# ESP32-S31 register map
Vendor: ESPRESSIF SYSTEMS (SHANGHAI) CO., LTD.; Series: ESP32 S-Series; File version: 1
CPU: RV32IMAFC r0p0, little endian, no MPU, FPU, 0 interrupt priority bits
Address unit: 32 bits
Registers are 32-bit, read-write, reset 0x0 unless marked. A register's access mark holds for its fields unless they carry their own. Offsets are from the block's base; [hi:lo] are bit positions; {n}, {i} and the like mark numbered series.

## EFUSE — eFuse Controller
Base 0x20715000
{0x0+4i} PGM_DATA{i} (i=0..7) — Represents pgm_data{i}
  [31:0] PGM_DATA — Configures the %sth 32-bit data to be programmed.
{0x20+4i} PGM_CHECK_VALUE{i} (i=0..2) — Represents pgm_check_value{i}
  [31:0] PGM_RS_DATA — Configures the %sth RS code to be programmed.
0x2C RD_WR_DIS ro — Represents rd_wr_dis
  [31:0] WR_DIS — Represents whether programming of individual eFuse memory bit is disabled. For mapping between the bits of this field and the eFuse memory bits, please refer to Table ef{tab:efuse-block0-para} and Table ef{tab:efuse-block-1-10-para}.\\1: Disabled\\0: Enabled\\
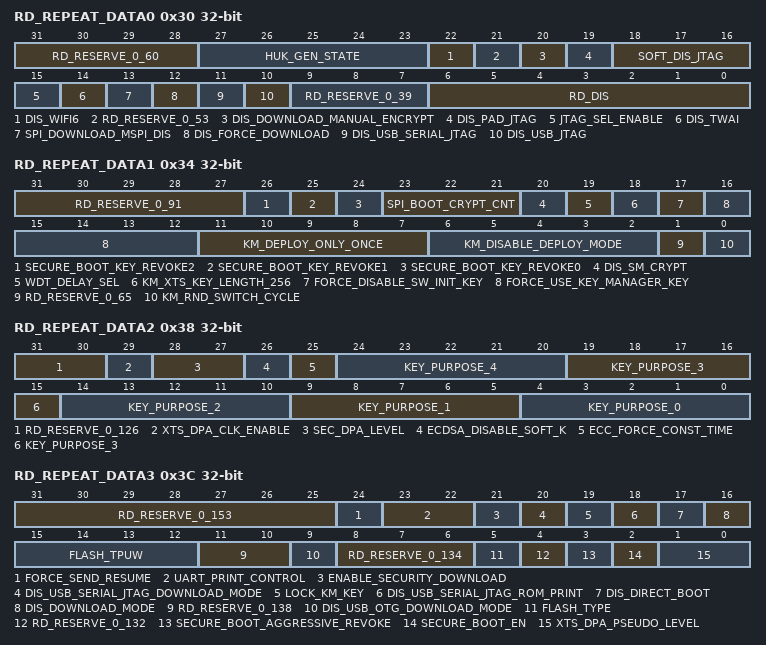
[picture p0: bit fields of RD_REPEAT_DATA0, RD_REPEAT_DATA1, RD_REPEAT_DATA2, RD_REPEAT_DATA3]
0x30 RD_REPEAT_DATA0 access per field — Represents rd_repeat_data
  [31:28] RD_RESERVE_0_60 rw
  [27:23] HUK_GEN_STATE ro — Represents the control of validation of HUK generate mode. Odd of 1 is invalid, even of 1 is valid.
  [22] DIS_WIFI6 ro — Represents thether the WIFI6 feature is enable or disabled. 1: WIFI6 is disable, 0: WIFI6 is enabled.
  [21] RD_RESERVE_0_53 rw
  [20] DIS_DOWNLOAD_MANUAL_ENCRYPT ro — Represents whether flash encrypt function is disabled or enabled(except in SPI boot mode).\\ 1: disabled\\ 0: enabled\\
  [19] DIS_PAD_JTAG ro — Represents whether JTAG is disabled in the hard way(permanently).\\ 1: disabled\\ 0: enabled\\
  [18:16] SOFT_DIS_JTAG ro — Represents whether JTAG is disabled in soft way.\\ Odd number: disabled\\ Even number: enabled\\
  [15] JTAG_SEL_ENABLE ro — Represents whether the selection between usb_to_jtag and pad_to_jtag through strapping gpio15 when both EFUSE_DIS_PAD_JTAG and EFUSE_DIS_USB_JTAG are equal to 0 is enabled or disabled.\\ 1: enabled\\ 0: disabled\\
  [14] DIS_TWAI ro — Represents whether TWAI function is disabled or enabled.\\ 1: disabled\\ 0: enabled\\
  [13] SPI_DOWNLOAD_MSPI_DIS ro — Represents whether SPI0 controller during boot_mode_download is disabled or enabled.\\ 1: disabled\\ 0: enabled\\
  [12] DIS_FORCE_DOWNLOAD ro — Represents whether the function that forces chip into download mode is disabled or enabled.\\ 1: disabled\\ 0: enabled\\
  [11] DIS_USB_SERIAL_JTAG ro — Represents whether USB-Serial-JTAG is disabled or enabled.\\ 1: disabled\\ 0: enabled\\
  [10] DIS_USB_JTAG ro — Represents whether the function of usb switch to jtag is disabled or enabled.\\ 1: disabled\\ 0: enabled\\
  [9:7] RD_RESERVE_0_39 rw
  [6:0] RD_DIS ro — Represents whether reading of individual eFuse block(block4~block9) is disabled or enabled.\\ 1: disabled\\ 0: enabled\\
0x34 RD_REPEAT_DATA1 access per field — Represents rd_repeat_data
  [31:27] RD_RESERVE_0_91 rw
  [26] SECURE_BOOT_KEY_REVOKE2 ro — Represents whether revoking third secure boot key is enabled or disabled.\\ 1: enabled\\ 0: disabled\\
  [25] SECURE_BOOT_KEY_REVOKE1 ro — Represents whether revoking second secure boot key is enabled or disabled.\\ 1: enabled\\ 0: disabled\\
  [24] SECURE_BOOT_KEY_REVOKE0 ro — Represents whether revoking first secure boot key is enabled or disabled.\\ 1: enabled\\ 0: disabled\\
  [23:21] SPI_BOOT_CRYPT_CNT ro — Represents whether SPI boot encrypt/decrypt is disabled or enabled.\\ Odd number of 1: enabled\\ Even number of 1: disabled\\
  [20] DIS_SM_CRYPT ro — Represents whether to disable all the SM crypto functions, including SM2, SM3.\\ 1: disabled\\ 0: enabled\\
  [19] WDT_DELAY_SEL ro — Represents the threshold level of the RTC watchdog STG0 timeout.\\0: Original threshold configuration value of STG0 *2 \\1: Original threshold configuration value of STG0 *4 \\2: Original threshold configuration value of STG0 *8 \\3: Original threshold configuration value of STG0 *16 \\
  [18] KM_XTS_KEY_LENGTH_256 ro — Represents whether to configure flash encryption use xts-128 key. else use xts-256 key. \\ 0: 128-bit key \\ 1: 256-bit key\\
  [17] FORCE_DISABLE_SW_INIT_KEY ro — Represents whether to disable software written init key, and force use efuse_init_key.
  [16:12] FORCE_USE_KEY_MANAGER_KEY ro — Represents whether corresponding key must come from key manager. 1 is true, 0 is false.\\ 0: ecsda\\ 1: flash\\ 2: reserved\\ 3: reserved\\ 4: psram\\
  [11:7] KM_DEPLOY_ONLY_ONCE ro — Represents whether corresponding key can only be deployed once. 1 is true, 0 is false. \\ 0: ecsda\\ 1: flash & spi boot srambler\\ 2: hmac & aes\\ 3: ds & rma nonce\\ 4: psram\\
  [6:2] KM_DISABLE_DEPLOY_MODE ro — Represents whether the deploy mode of key manager is disable or not. \\ 1: disabled \\ 0: enabled.\\ bit 0: ecsda, bit 1: flash & spi boot srambler, bit2: hmac & aes, bit3: ds & rma nonce, bit4: psram
  [1] RD_RESERVE_0_65 rw
  [0] KM_RND_SWITCH_CYCLE ro — Represents the control of key manager random number switch cycle. 0: control by register. 1: 8 km clk cycles. 2: 16 km cycles. 3: 32 km cycles
0x38 RD_REPEAT_DATA2 access per field — Represents rd_repeat_data
  [31:30] RD_RESERVE_0_126 rw
  [29] XTS_DPA_CLK_ENABLE ro — Represents whether to enable xts clock anti-dpa attack function.\\0: Disabled. \\1: Enabled\\
  [28:27] SEC_DPA_LEVEL ro — Represents the spa secure level by configuring the clock random divide mode.
  [26] ECDSA_DISABLE_SOFT_K ro — Represents whether permanently turn off ECDSA software set KEY.\\ 1: turn off\\ 0: turn on\\
  [25] ECC_FORCE_CONST_TIME ro — Represents whether permanently turn on ECC const-time mode. \\ 1: turn on\\ 0: turn off\\
  [5n+4:5n] KEY_PURPOSE_{n} ro (n=0..4) — Represents the purpose of Key{n}.
0x3C RD_REPEAT_DATA3 access per field — Represents rd_repeat_data
  [31:25] RD_RESERVE_0_153 rw
  [24] FORCE_SEND_RESUME ro — Represents whether ROM code is forced to send a resume command during SPI boot.\\ 1: forced\\ 0:not forced\\
  [23:22] UART_PRINT_CONTROL ro — Represents the type of UART printing.\\ 00: force enable printing\\ 01: enable printing when GPIO8 is reset at low level\\ 10: enable printing when GPIO8 is reset at high level\\ 11: force disable printing\\
  [21] ENABLE_SECURITY_DOWNLOAD ro — Represents whether security download is enabled or disabled.\\ 1: enabled\\ 0: disabled\\
  [20] DIS_USB_SERIAL_JTAG_DOWNLOAD_MODE ro — Represents whether the USB-Serial-JTAG download function is disabled or enabled.\\ 1: Disable\\ 0: Enable\\
  [19] LOCK_KM_KEY ro — Represetns whether to lock the efuse xts key.\\ 1. Lock\\ 0: Unlock\\
  [18] DIS_USB_SERIAL_JTAG_ROM_PRINT ro — Represents whether print from USB-Serial-JTAG is disabled or enabled.\\ 1: disabled\\ 0: enabled\\
  [17] DIS_DIRECT_BOOT ro — Represents whether direct boot mode is disabled or enabled.\\ 1: disabled\\ 0: enabled\\
  [16] DIS_DOWNLOAD_MODE ro — Represents whether Download mode is disabled or enabled.\\ 1: disabled\\ 0: enabled\\
  [15:12] FLASH_TPUW ro — Represents the flash waiting time after power-up, in unit of ms. When the value less than 15, the waiting time is the programmed value. Otherwise, the waiting time is 2 times the programmed value.
  [11:10] RD_RESERVE_0_138 rw
  [9] DIS_USB_OTG_DOWNLOAD_MODE ro — Set this bit to disable download via USB-OTG.
  [8:6] RD_RESERVE_0_134 rw
  [5] FLASH_TYPE ro — flash type: 0: nor flash, 1: nand flash
  [4] RD_RESERVE_0_132 rw
  [3] SECURE_BOOT_AGGRESSIVE_REVOKE ro — Represents whether revoking aggressive secure boot is enabled or disabled.\\ 1: enabled.\\ 0: disabled\\
  [2] SECURE_BOOT_EN ro — Represents whether secure boot is enabled or disabled.\\ 1: enabled\\ 0: disabled\\
  [1:0] XTS_DPA_PSEUDO_LEVEL ro — Represents the control of the xts pseudo-round anti-dpa attack function.\\ 0: controlled by register.\\ 1-3: the higer the value is, the more pseudo-rounds are inserted to the xts-aes calculation\\
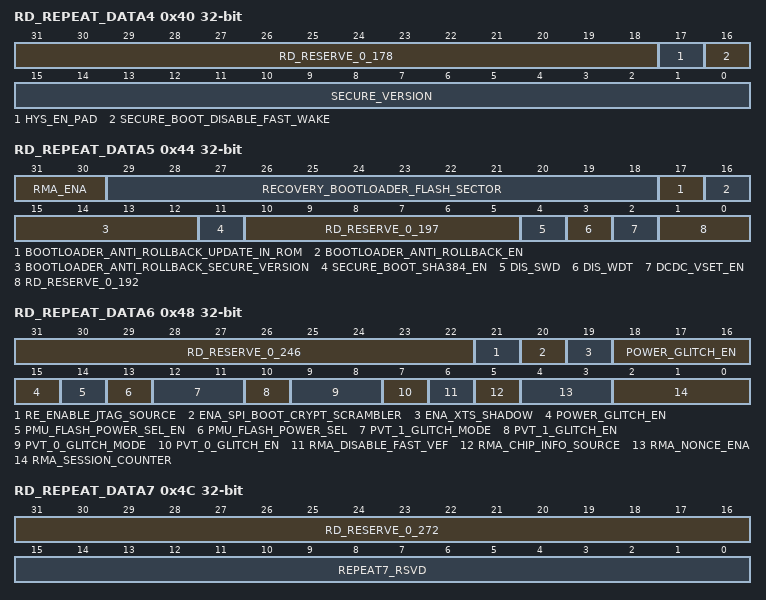
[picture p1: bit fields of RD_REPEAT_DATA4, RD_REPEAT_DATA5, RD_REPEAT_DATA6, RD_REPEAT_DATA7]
0x40 RD_REPEAT_DATA4 access per field — Represents rd_repeat_data
  [31:18] RD_RESERVE_0_178 rw
  [17] HYS_EN_PAD ro — Represents whether the hysteresis function of corresponding PAD is enabled.\\ 1: enabled\\ 0:disabled\\
  [16] SECURE_BOOT_DISABLE_FAST_WAKE ro — Represents whether FAST VERIFY ON WAKE is disabled or enabled when Secure Boot is enabled.\\ 1: disabled\\ 0: enabled\\
  [15:0] SECURE_VERSION ro — Represents the version used by ESP-IDF anti-rollback feature.
0x44 RD_REPEAT_DATA5 access per field — Represents rd_repeat_data
  [31:30] RMA_ENA ro — Represents whether rma function is supported in download mode.\\ 2'b01/2'b10: enabled\\2'b00/2'b11: disabled\\
  [29:18] RECOVERY_BOOTLOADER_FLASH_SECTOR ro — Represents the starting flash sector (flash sector size is 0x1000) of the recovery bootloader used by the ROM bootloader If the primary bootloader fails. 0 and 0xFFF - this feature is disabled.
  [17] BOOTLOADER_ANTI_ROLLBACK_UPDATE_IN_ROM ro — Represents whether the ani-rollback SECURE_VERSION will be updated from the ROM bootloader.\\1: Enable\\0: Disable\\
  [16] BOOTLOADER_ANTI_ROLLBACK_EN ro — Represents whether the ani-rollback check for the 2nd stage bootloader is enabled.\\1: Enabled\\0: Disabled\\
  [15:12] BOOTLOADER_ANTI_ROLLBACK_SECURE_VERSION ro — Represents the anti-rollback secure version of the 2nd stage bootloader used by the ROM bootloader.
  [11] SECURE_BOOT_SHA384_EN ro — Represents whether secure boot using SHA-384 is enabled. 0: Disable 1: Enable
  [10:5] RD_RESERVE_0_197 rw
  [4] DIS_SWD ro — Set this bit to disable super-watchdog.
  [3] DIS_WDT ro — Set this bit to disable watch dog.
  [2] DCDC_VSET_EN ro — Select dcdc vset use efuse_dcdc_vset.
  [1:0] RD_RESERVE_0_192 rw
0x48 RD_REPEAT_DATA6 access per field — Represents rd_repeat_data
  [31:22] RD_RESERVE_0_246 rw
  [21] RE_ENABLE_JTAG_SOURCE ro — Represents which Crypto peripheral is selected for renabling JTAG. \\ 0: RMA\\ 1: HMAC\\
  [20] ENA_SPI_BOOT_CRYPT_SCRAMBLER ro — Represents whether to enable ciphertext scrambler for external memory . \\ 0: Disabled\\ 1: Enabled\\
  [19] ENA_XTS_SHADOW ro — Represents whether to enable XTS-AES shadow core countermeasure against fault injection attacks. \\ 0: Disabled\\ 1: Enabled\\
  [18:15] POWER_GLITCH_EN ro — set these bit enable power glitch enable
  [14] PMU_FLASH_POWER_SEL_EN ro — FLASH power select enable signal. 1'b1 : validates EFUSE_PMU_FLASH_POWER_SEL 1'b0: invalidates EFUSE_PMU_FLASH_POWER_SEL
  [13] PMU_FLASH_POWER_SEL ro — FLASH power select.\\ 1'b1: use 3.3V\\1'b0: use 1.8V
  [12:11] PVT_1_GLITCH_MODE ro — Use to configure glitch mode
  [10] PVT_1_GLITCH_EN ro — Represents whether to enable PVT power glitch monitor function.\\1:Enable. \\0:Disable
  [9:8] PVT_0_GLITCH_MODE ro — Use to configure glitch mode
  [7] PVT_0_GLITCH_EN ro — Represents whether to enable PVT power glitch monitor function.\\1:Enable. \\0:Disable
  [6] RMA_DISABLE_FAST_VEF ro — Represents whether disable FAST_VEF in RMA session.\\1: disable\\0: enable\\
  [5] RMA_CHIP_INFO_SOURCE ro — Represents whether HUK_info is selected as the source for calculating CHIP_info in RMA.\\1: use HUK_info\\ 0: use UNIQ_id\\
  [4:3] RMA_NONCE_ENA ro — Represents whether random number NONCE is used in RMA and whether the KM module is used to generate the NONCE\\. 2'bx0: No NONCE\\ 2'b1x: Use KM generate NONCE.\\
  [2:0] RMA_SESSION_COUNTER ro — Represents the number of times the RMA session has been entered.
0x4C RD_REPEAT_DATA7 access per field — Represents rd_repeat_data
  [31:16] RD_RESERVE_0_272 rw
  [15:0] REPEAT7_RSVD ro — Reserved.
0x50 RD_MAC_SYS0 ro — Represents rd_mac_sys
  [31:0] MAC_0 — Represents MAC address. Low 32-bit.
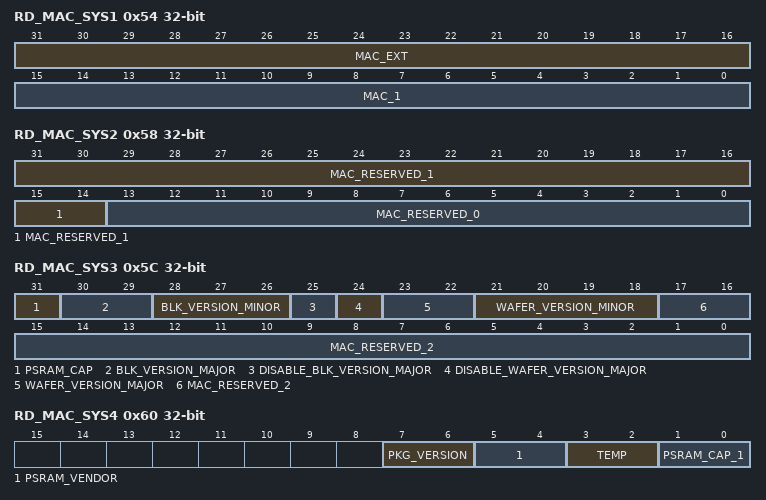
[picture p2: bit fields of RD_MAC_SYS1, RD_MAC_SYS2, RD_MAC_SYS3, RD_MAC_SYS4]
0x54 RD_MAC_SYS1 ro — Represents rd_mac_sys
  [31:16] MAC_EXT — Represents the extended bits of MAC address.
  [15:0] MAC_1 — Represents MAC address. High 16-bit.
0x58 RD_MAC_SYS2 ro — Represents rd_mac_sys
  [31:14] MAC_RESERVED_1 — Reserved.
  [13:0] MAC_RESERVED_0 — Reserved.
0x5C RD_MAC_SYS3 access per field — Represents rd_mac_sys
  [31] PSRAM_CAP rw
  [30:29] BLK_VERSION_MAJOR rw
  [28:26] BLK_VERSION_MINOR rw
  [25] DISABLE_BLK_VERSION_MAJOR rw
  [24] DISABLE_WAFER_VERSION_MAJOR rw
  [23:22] WAFER_VERSION_MAJOR rw
  [21:18] WAFER_VERSION_MINOR ro — Represents the first 14-bit of zeroth part of system data.
  [17:0] MAC_RESERVED_2 ro — Reserved.
0x60 RD_MAC_SYS4 access per field — Represents rd_mac_sys
  [7:6] PKG_VERSION rw
  [5:4] PSRAM_VENDOR rw
  [3:2] TEMP rw
  [1:0] PSRAM_CAP_1 ro — Represents the second 32-bit of zeroth part of system data.
0x64 RD_MAC_SYS5 ro — Represents rd_mac_sys
  [31:0] SYS_DATA_PART0_2 — Represents the third 32-bit of zeroth part of system data.
{0x68+4i} RD_SYS_PART1_DATA{i} (i=0..7) ro — Represents rd_sys_part1_data{i}
  [31:0] SYS_DATA_PART1 — Represents the zeroth 32-bit of first part of system data.
{0x88+4i} RD_USR_DATA{i} (i=0..7) ro — Represents rd_usr_data{i}
  [31:0] USR_DATA — Represents the zeroth 32-bit of block3 (user).
{0xA8+4i} RD_KEY0_DATA{i} (i=0..7) ro — Represents rd_key0_data{i}
  [31:0] KEY0_DATA — Represents the zeroth 32-bit of key0.
{0xC8+4i} RD_KEY1_DATA{i} (i=0..7) ro — Represents rd_key1_data{i}
  [31:0] KEY1_DATA — Represents the zeroth 32-bit of key1.
{0xE8+4i} RD_KEY2_DATA{i} (i=0..7) ro — Represents rd_key2_data{i}
  [31:0] KEY2_DATA — Represents the zeroth 32-bit of key2.
{0x108+4i} RD_KEY3_DATA{i} (i=0..7) ro — Represents rd_key3_data{i}
  [31:0] KEY3_DATA — Represents the zeroth 32-bit of key3.
{0x128+4i} RD_KEY4_DATA{i} (i=0..7) ro — Represents rd_key4_data{i}
  [31:0] KEY4_DATA — Represents the zeroth 32-bit of key4.
0x148 RD_SYS_PART2_DATA0 ro — Represents rd_sys_part2_data
  [31:0] SYS_DATA_PART2_0 — Represents the zeroth 32-bit of second part of system data.
0x14C RD_SYS_PART2_DATA1 ro — Represents rd_sys_part2_data
  [31:0] SYS_DATA_PART2_1 — Represents the first 32-bit of second part of system data.
0x150 RD_SYS_PART2_DATA2 ro — Represents rd_sys_part2_data
  [31:0] SYS_DATA_PART2_2 — Represents the second 32-bit of second part of system data.
0x154 RD_SYS_PART2_DATA3 ro — Represents rd_sys_part2_data
  [31:0] SYS_DATA_PART2_3 — Represents the third 32-bit of second part of system data.
0x158 RD_SYS_PART2_DATA4 ro — Represents rd_sys_part2_data
  [31:0] SYS_DATA_PART2_4 — Represents the fourth 32-bit of second part of system data.
0x15C RD_SYS_PART2_DATA5 ro — Represents rd_sys_part2_data
  [31:0] SYS_DATA_PART2_5 — Represents the fifth 32-bit of second part of system data.
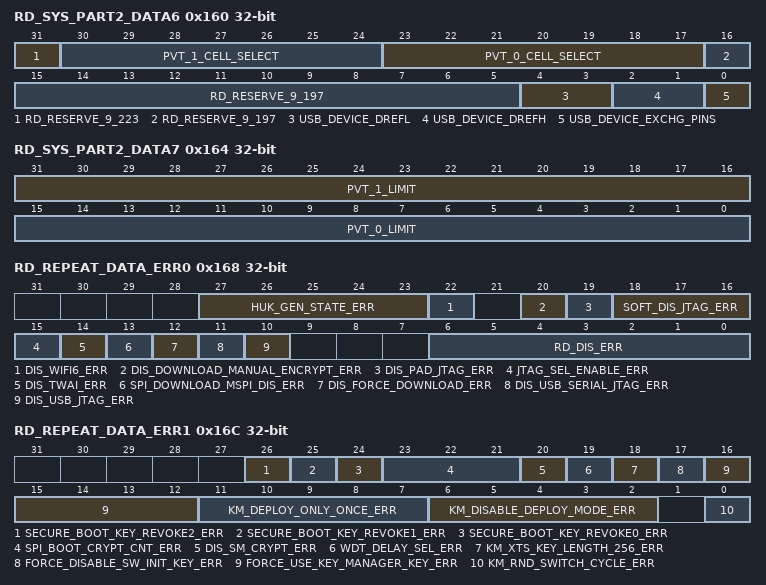
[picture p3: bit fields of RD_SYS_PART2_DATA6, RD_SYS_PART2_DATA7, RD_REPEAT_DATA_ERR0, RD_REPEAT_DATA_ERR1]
0x160 RD_SYS_PART2_DATA6 access per field — Represents rd_sys_part2_data
  [31] RD_RESERVE_9_223 rw
  [30:24] PVT_1_CELL_SELECT ro — Power glitch monitor PVT cell select.
  [23:17] PVT_0_CELL_SELECT ro — Power glitch monitor PVT cell select.
  [16:5] RD_RESERVE_9_197 rw
  [4:3] USB_DEVICE_DREFL ro — Represents the usb device single-end input low threhold, 0.8 V to 1.04 V with step of 80 mV.
  [2:1] USB_DEVICE_DREFH ro — Represents the single-end input threhold vrefh, 1.76 V to 2 V with step of 80 mV.
  [0] USB_DEVICE_EXCHG_PINS ro — Represents whether enable usb device exchange pins of D+ and D- or not. \\ 1: enabled\\ 0: disabled\\
0x164 RD_SYS_PART2_DATA7 ro — Represents rd_sys_part2_data
  [31:16] PVT_1_LIMIT — Power glitch monitor threthold.
  [15:0] PVT_0_LIMIT — Power glitch monitor threthold.
0x168 RD_REPEAT_DATA_ERR0 ro — Represents rd_repeat_data_err
  [27:23] HUK_GEN_STATE_ERR — Represents the programming error of EFUSE_HUK_GEN_STATE
  [22] DIS_WIFI6_ERR — Represents the programming error of EFUSE_DIS_WIFI6
  [20] DIS_DOWNLOAD_MANUAL_ENCRYPT_ERR — Represents the programming error of EFUSE_DIS_DOWNLOAD_MANUAL_ENCRYPT
  [19] DIS_PAD_JTAG_ERR — Represents the programming error of EFUSE_DIS_PAD_JTAG
  [18:16] SOFT_DIS_JTAG_ERR — Represents the programming error of EFUSE_SOFT_DIS_JTAG
  [15] JTAG_SEL_ENABLE_ERR — Represents the programming error of EFUSE_JTAG_SEL_ENABLE
  [14] DIS_TWAI_ERR — Represents the programming error of EFUSE_DIS_TWAI
  [13] SPI_DOWNLOAD_MSPI_DIS_ERR — Represents the programming error of EFUSE_SPI_DOWNLOAD_MSPI_DIS
  [12] DIS_FORCE_DOWNLOAD_ERR — Represents the programming error of EFUSE_DIS_FORCE_DOWNLOAD
  [11] DIS_USB_SERIAL_JTAG_ERR — Represents the programming error of EFUSE_DIS_USB_SERIAL_JTAG
  [10] DIS_USB_JTAG_ERR — Represents the programming error of EFUSE_DIS_USB_JTAG
  [6:0] RD_DIS_ERR — Represents the programming error of EFUSE_RD_DIS
0x16C RD_REPEAT_DATA_ERR1 ro — Represents rd_repeat_data_err
  [26] SECURE_BOOT_KEY_REVOKE2_ERR — Represents the programming error of EFUSE_SECURE_BOOT_KEY_REVOKE2
  [25] SECURE_BOOT_KEY_REVOKE1_ERR — Represents the programming error of EFUSE_SECURE_BOOT_KEY_REVOKE1
  [24] SECURE_BOOT_KEY_REVOKE0_ERR — Represents the programming error of EFUSE_SECURE_BOOT_KEY_REVOKE0
  [23:21] SPI_BOOT_CRYPT_CNT_ERR — Represents the programming error of EFUSE_SPI_BOOT_CRYPT_CNT
  [20] DIS_SM_CRYPT_ERR — Represents the programming error of EFUSE_DIS_SM_CRYPT
  [19] WDT_DELAY_SEL_ERR — Represents the programming error of EFUSE_WDT_DELAY_SEL
  [18] KM_XTS_KEY_LENGTH_256_ERR — Represents the programming error of EFUSE_KM_XTS_KEY_LENGTH_256
  [17] FORCE_DISABLE_SW_INIT_KEY_ERR — Represents the programming error of EFUSE_FORCE_DISABLE_SW_INIT_KEY
  [16:12] FORCE_USE_KEY_MANAGER_KEY_ERR — Represents the programming error of EFUSE_FORCE_USE_KEY_MANAGER_KEY
  [11:7] KM_DEPLOY_ONLY_ONCE_ERR — Represents the programming error of EFUSE_KM_DEPLOY_ONLY_ONCE
  [6:2] KM_DISABLE_DEPLOY_MODE_ERR — Represents the programming error of EFUSE_KM_DISABLE_DEPLOY_MODE
  [0] KM_RND_SWITCH_CYCLE_ERR — Represents the programming error of EFUSE_KM_RND_SWITCH_CYCLE
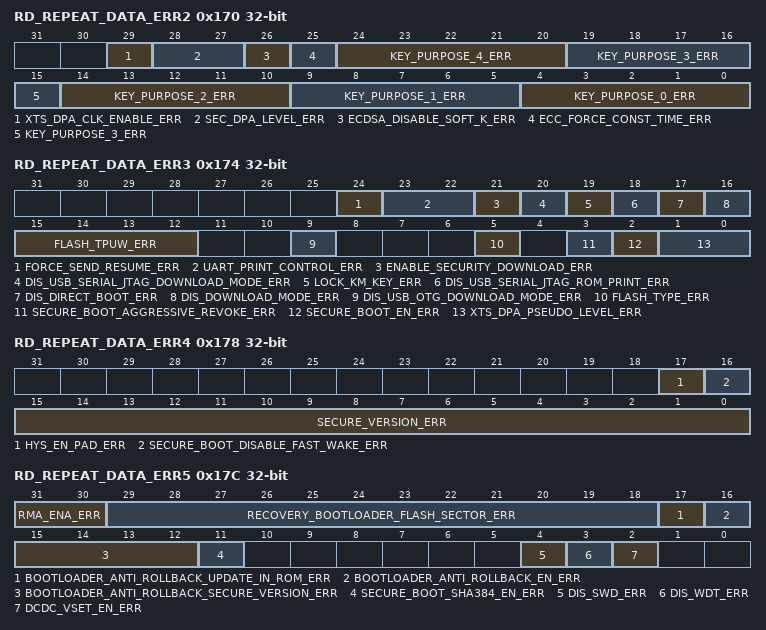
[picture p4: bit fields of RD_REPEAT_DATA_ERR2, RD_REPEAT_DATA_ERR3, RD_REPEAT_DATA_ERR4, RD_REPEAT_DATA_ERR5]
0x170 RD_REPEAT_DATA_ERR2 ro — Represents rd_repeat_data_err
  [29] XTS_DPA_CLK_ENABLE_ERR — Represents the programming error of EFUSE_XTS_DPA_CLK_ENABLE
  [28:27] SEC_DPA_LEVEL_ERR — Represents the programming error of EFUSE_SEC_DPA_LEVEL
  [26] ECDSA_DISABLE_SOFT_K_ERR — Represents the programming error of EFUSE_ECDSA_DISABLE_SOFT_K
  [25] ECC_FORCE_CONST_TIME_ERR — Represents the programming error of EFUSE_ECC_FORCE_CONST_TIME
  [5n+4:5n] KEY_PURPOSE_{n}_ERR (n=0..4) — Represents the programming error of EFUSE_KEY_PURPOSE_{n}
0x174 RD_REPEAT_DATA_ERR3 ro — Represents rd_repeat_data_err
  [24] FORCE_SEND_RESUME_ERR — Represents the programming error of EFUSE_FORCE_SEND_RESUME
  [23:22] UART_PRINT_CONTROL_ERR — Represents the programming error of EFUSE_UART_PRINT_CONTROL
  [21] ENABLE_SECURITY_DOWNLOAD_ERR — Represents the programming error of EFUSE_ENABLE_SECURITY_DOWNLOAD
  [20] DIS_USB_SERIAL_JTAG_DOWNLOAD_MODE_ERR — Represents the programming error of EFUSE_DIS_USB_SERIAL_JTAG_DOWNLOAD_MODE
  [19] LOCK_KM_KEY_ERR — Represents the programming error of EFUSE_LOCK_KM_KEY
  [18] DIS_USB_SERIAL_JTAG_ROM_PRINT_ERR — Represents the programming error of EFUSE_DIS_USB_SERIAL_JTAG_ROM_PRINT
  [17] DIS_DIRECT_BOOT_ERR — Represents the programming error of EFUSE_DIS_DIRECT_BOOT
  [16] DIS_DOWNLOAD_MODE_ERR — Represents the programming error of EFUSE_DIS_DOWNLOAD_MODE
  [15:12] FLASH_TPUW_ERR — Represents the programming error of EFUSE_FLASH_TPUW
  [9] DIS_USB_OTG_DOWNLOAD_MODE_ERR — Represents the programming error of EFUSE_DIS_USB_OTG_DOWNLOAD_MODE
  [5] FLASH_TYPE_ERR — Represents the programming error of EFUSE_FLASH_TYPE
  [3] SECURE_BOOT_AGGRESSIVE_REVOKE_ERR — Represents the programming error of EFUSE_SECURE_BOOT_AGGRESSIVE_REVOKE
  [2] SECURE_BOOT_EN_ERR — Represents the programming error of EFUSE_SECURE_BOOT_EN
  [1:0] XTS_DPA_PSEUDO_LEVEL_ERR — Represents the programming error of EFUSE_XTS_DPA_PSEUDO_LEVEL
0x178 RD_REPEAT_DATA_ERR4 ro — Represents rd_repeat_data_err
  [17] HYS_EN_PAD_ERR — Represents the programming error of EFUSE_HYS_EN_PAD
  [16] SECURE_BOOT_DISABLE_FAST_WAKE_ERR — Represents the programming error of EFUSE_SECURE_BOOT_DISABLE_FAST_WAKE
  [15:0] SECURE_VERSION_ERR — Represents the programming error of EFUSE_SECURE_VERSION
0x17C RD_REPEAT_DATA_ERR5 ro — Represents rd_repeat_data_err
  [31:30] RMA_ENA_ERR — Represents the programming error of EFUSE_RMA_ENA
  [29:18] RECOVERY_BOOTLOADER_FLASH_SECTOR_ERR — Represents the programming error of EFUSE_RECOVERY_BOOTLOADER_FLASH_SECTOR
  [17] BOOTLOADER_ANTI_ROLLBACK_UPDATE_IN_ROM_ERR — Represents the programming error of EFUSE_BOOTLOADER_ANTI_ROLLBACK_UPDATE_IN_ROM
  [16] BOOTLOADER_ANTI_ROLLBACK_EN_ERR — Represents the programming error of EFUSE_BOOTLOADER_ANTI_ROLLBACK_EN
  [15:12] BOOTLOADER_ANTI_ROLLBACK_SECURE_VERSION_ERR — Represents the programming error of EFUSE_BOOTLOADER_ANTI_ROLLBACK_SECURE_VERSION
  [11] SECURE_BOOT_SHA384_EN_ERR — Represents the programming error of EFUSE_SECURE_BOOT_SHA384_EN
  [4] DIS_SWD_ERR — Represents the programming error of EFUSE_DIS_SWD
  [3] DIS_WDT_ERR — Represents the programming error of EFUSE_DIS_WDT
  [2] DCDC_VSET_EN_ERR — Represents the programming error of EFUSE_DCDC_VSET_EN
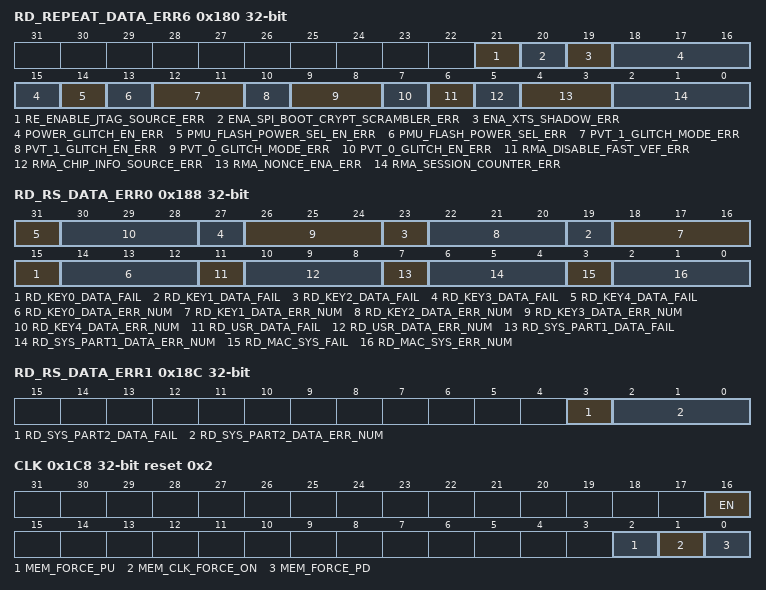
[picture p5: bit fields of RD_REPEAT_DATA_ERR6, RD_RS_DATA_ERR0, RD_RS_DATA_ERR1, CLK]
0x180 RD_REPEAT_DATA_ERR6 ro — Represents rd_repeat_data_err
  [21] RE_ENABLE_JTAG_SOURCE_ERR — Represents the programming error of EFUSE_RE_ENABLE_JTAG_SOURCE
  [20] ENA_SPI_BOOT_CRYPT_SCRAMBLER_ERR — Represents the programming error of EFUSE_ENA_SPI_BOOT_CRYPT_SCRAMBLER
  [19] ENA_XTS_SHADOW_ERR — Represents the programming error of EFUSE_ENA_XTS_SHADOW
  [18:15] POWER_GLITCH_EN_ERR — Represents the programming error of EFUSE_POWER_GLITCH_EN
  [14] PMU_FLASH_POWER_SEL_EN_ERR — Represents the programming error of EFUSE_PMU_FLASH_POWER_SEL_EN
  [13] PMU_FLASH_POWER_SEL_ERR — Represents the programming error of EFUSE_PMU_FLASH_POWER_SEL
  [12:11] PVT_1_GLITCH_MODE_ERR — Represents the programming error of EFUSE_PVT_1_GLITCH_MODE
  [10] PVT_1_GLITCH_EN_ERR — Represents the programming error of EFUSE_PVT_1_GLITCH_EN
  [9:8] PVT_0_GLITCH_MODE_ERR — Represents the programming error of EFUSE_PVT_0_GLITCH_MODE
  [7] PVT_0_GLITCH_EN_ERR — Represents the programming error of EFUSE_PVT_0_GLITCH_EN
  [6] RMA_DISABLE_FAST_VEF_ERR — Represents the programming error of EFUSE_RMA_DISABLE_FAST_VEF
  [5] RMA_CHIP_INFO_SOURCE_ERR — Represents the programming error of EFUSE_RMA_CHIP_INFO_SOURCE
  [4:3] RMA_NONCE_ENA_ERR — Represents the programming error of EFUSE_RMA_NONCE_ENA
  [2:0] RMA_SESSION_COUNTER_ERR — Represents the programming error of EFUSE_RMA_SESSION_COUNTER
0x184 RD_REPEAT_DATA_ERR7 ro — Represents rd_repeat_data_err
  [15:0] REPEAT7_RSVD_ERR — Represents the programming error of EFUSE_REPEAT7_RSVD
0x188 RD_RS_DATA_ERR0 ro — Represents rd_rs_data_err
  [4n+15] RD_KEY{n}_DATA_FAIL (n=0..4) — Represents error status of register.\\0: Means no failure and that the data of rd_key{n}_data is reliable\\ 1: Means that programming rd_key{n}_data failed and the number of error bytes is over 6.
  [4n+14:4n+12] RD_KEY{n}_DATA_ERR_NUM (n=0..4) — Represents the error number of registers.\\The value of this signal means the number of error bytes in rd_key{n}_data
  [11] RD_USR_DATA_FAIL — Represents error status of register.\\0: Means no failure and that the data of rd_usr_data is reliable\\ 1: Means that programming rd_usr_data failed and the number of error bytes is over 6.
  [10:8] RD_USR_DATA_ERR_NUM — Represents the error number of registers.\\The value of this signal means the number of error bytes in rd_usr_data
  [7] RD_SYS_PART1_DATA_FAIL — Represents error status of register.\\0: Means no failure and that the data of rd_sys_part1_data is reliable\\ 1: Means that programming rd_sys_part1_data failed and the number of error bytes is over 6.
  [6:4] RD_SYS_PART1_DATA_ERR_NUM — Represents the error number of registers.\\The value of this signal means the number of error bytes in rd_sys_part1_data
  [3] RD_MAC_SYS_FAIL — Represents error status of register.\\0: Means no failure and that the data of rd_mac_sys is reliable\\ 1: Means that programming rd_mac_sys failed and the number of error bytes is over 6.
  [2:0] RD_MAC_SYS_ERR_NUM — Represents the error number of registers.\\The value of this signal means the number of error bytes in rd_mac_sys
0x18C RD_RS_DATA_ERR1 ro — Represents rd_rs_data_err
  [3] RD_SYS_PART2_DATA_FAIL — Represents error status of register.\\0: Means no failure and that the data of rd_sys_part2_data is reliable\\ 1: Means that programming rd_sys_part2_data failed and the number of error bytes is over 6.
  [2:0] RD_SYS_PART2_DATA_ERR_NUM — Represents the error number of registers.\\The value of this signal means the number of error bytes in rd_sys_part2_data
0x190 DATE reset 0x2509194 — eFuse version register.
  [27:0] DATE — Represents eFuse version. Date:2025-09-19 19:52:16, ScriptRev:abfb97fc087287a4eacd02828cb3ca8dd0d0e75f
0x1C8 CLK reset 0x2 — eFuse clcok configuration register.
  [16] EN — Configures whether to force enable eFuse register configuration clock signal.\\ 1: Force\\ 0: The clock is enabled only during the reading and writing of registers\\
  [2] MEM_FORCE_PU — Configures whether to force power up eFuse SRAM.\\ 1: Force\\ 0: No effect\\
  [1] MEM_CLK_FORCE_ON — Configures whether to force activate clock signal of eFuse SRAM.\\ 1: Force activate\\ 0: No effect\\
  [0] MEM_FORCE_PD — Configures whether to force power down eFuse SRAM.\\ 1: Force\\ 0: No effect\\
0x1CC CONF — eFuse operation mode configuraiton register
  [15:0] OP_CODE — Configures operation command type.\\ 0x5A5A: Program operation command\\ 0x5AA5: Read operation command\\ Other values: No effect\\
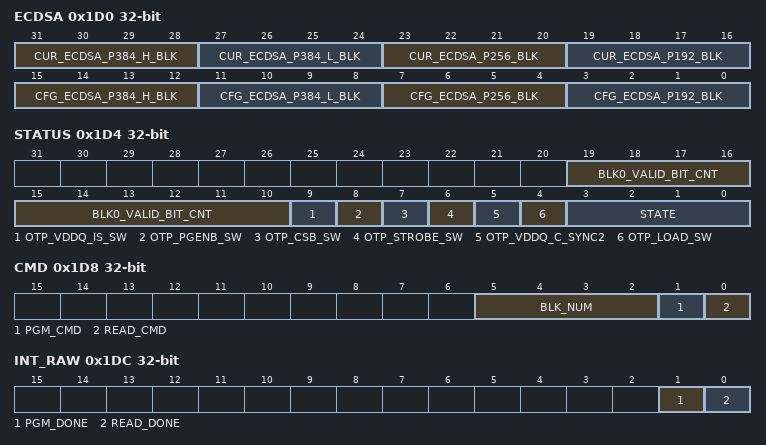
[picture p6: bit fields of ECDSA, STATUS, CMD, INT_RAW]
0x1D0 ECDSA access per field — eFuse status register.
  [31:28] CUR_ECDSA_P384_H_BLK ro — Represents which block is used for ECDSA P384 key high part output.
  [27:24] CUR_ECDSA_P384_L_BLK ro — Represents which block is used for ECDSA P384 key low part output.
  [23:20] CUR_ECDSA_P256_BLK ro — Represents which block is used for ECDSA P256 key output.
  [19:16] CUR_ECDSA_P192_BLK ro — Represents which block is used for ECDSA P192 key output.
  [15:12] CFG_ECDSA_P384_H_BLK rw — Configures which block to use for ECDSA P256 key high part output.
  [11:8] CFG_ECDSA_P384_L_BLK rw — Configures which block to use for ECDSA P384 key low part output.
  [7:4] CFG_ECDSA_P256_BLK rw — Configures which block to use for ECDSA P256 key output.
  [3:0] CFG_ECDSA_P192_BLK rw — Configures which block to use for ECDSA P192 key output.
0x1D4 STATUS ro — eFuse status register.
  [19:10] BLK0_VALID_BIT_CNT — Represents the number of block valid bit.
  [9] OTP_VDDQ_IS_SW — Represents the value of OTP_VDDQ_IS_SW.
  [8] OTP_PGENB_SW — Represents the value of OTP_PGENB_SW.
  [7] OTP_CSB_SW — Represents the value of OTP_CSB_SW.
  [6] OTP_STROBE_SW — Represents the value of OTP_STROBE_SW.
  [5] OTP_VDDQ_C_SYNC2 — Represents the value of OTP_VDDQ_C_SYNC2.
  [4] OTP_LOAD_SW — Represents the value of OTP_LOAD_SW.
  [3:0] STATE — Represents the state of the eFuse state machine.\\ 0: Reset state, the initial state after power-up\\ 1: Idle state\\ Other values: Non-idle state\\
0x1D8 CMD — eFuse command register.
  [5:2] BLK_NUM — Configures the serial number of the block to be programmed. Value 0-10 corresponds to block number 0-10, respectively.
  [1] PGM_CMD — Configures whether to send programing commands.\\ 1: Send\\ 0: No effect\\
  [0] READ_CMD — Configures whether to send read commands.\\ 1: Send\\ 0: No effect\\
0x1DC INT_RAW ro — eFuse raw interrupt register.
  [1] PGM_DONE — The raw interrupt status of EFUSE_PGM_DONE_INT.
  [0] READ_DONE — The raw interrupt status of EFUSE_READ_DONE_INT.
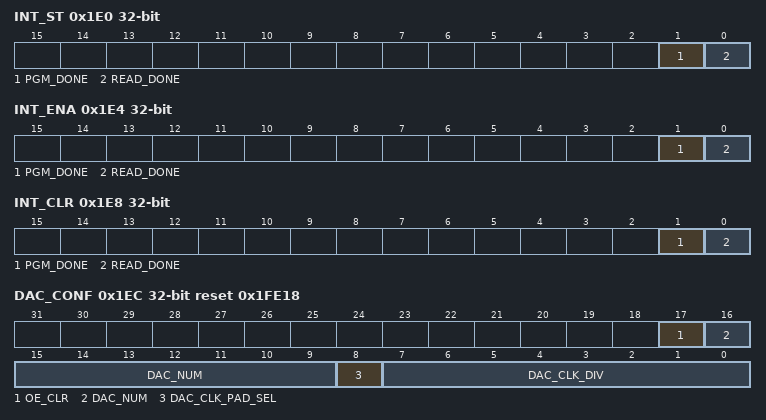
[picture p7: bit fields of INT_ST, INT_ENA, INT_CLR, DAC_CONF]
0x1E0 INT_ST ro — eFuse interrupt status register.
  [1] PGM_DONE — The masked interrupt status of EFUSE_PGM_DONE_INT.
  [0] READ_DONE — The masked interrupt status of EFUSE_READ_DONE_INT.
0x1E4 INT_ENA — eFuse interrupt enable register.
  [1] PGM_DONE — Write 1 to enable EFUSE_PGM_DONE_INT.
  [0] READ_DONE — Write 1 to enable EFUSE_READ_DONE_INT.
0x1E8 INT_CLR wo — eFuse interrupt clear register.
  [1] PGM_DONE write-1-clears — Write 1 to clear EFUSE_PGM_DONE_INT.
  [0] READ_DONE write-1-clears — Write 1 to clear EFUSE_READ_DONE_INT.
0x1EC DAC_CONF reset 0x1FE18 — Controls the eFuse programming voltage.
  [17] OE_CLR — Configures whether to reduce the power supply of programming voltage.\\ 0: Not reduce\\ 1: Reduce\\
  [16:9] DAC_NUM — Configures clock cycles for programming voltage to rise (VDDQ 2.5V, ramp-up 10mV for one-cycle). Measurement unit: a clock cycle divided by EFUSE_DAC_CLK_DIV.
  [8] DAC_CLK_PAD_SEL — Don't care.
  [7:0] DAC_CLK_DIV — Configures the division factor of the rising clock of the programming voltage (ramp-up slew rate be slower than 2.5V/250us, and ramp-up 10mV for one-cycle, so reg_dac_clk_div > fclk).
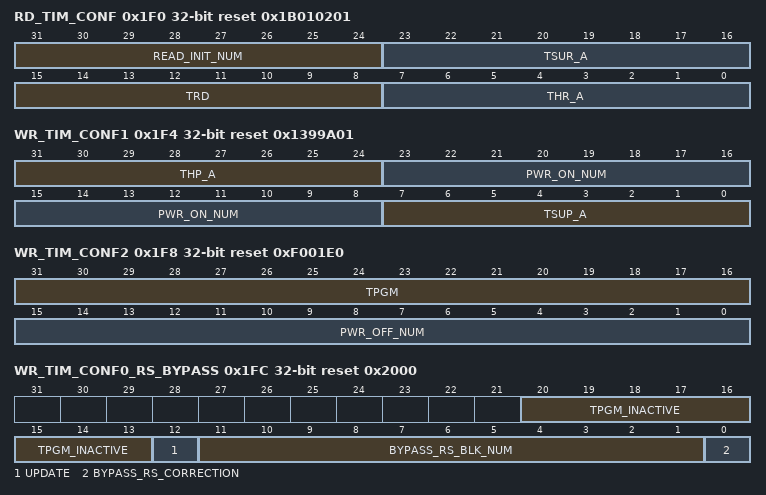
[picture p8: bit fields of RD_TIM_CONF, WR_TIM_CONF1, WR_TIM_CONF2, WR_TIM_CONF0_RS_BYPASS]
0x1F0 RD_TIM_CONF reset 0x1B010201 — Configures read timing parameters.
  [31:24] READ_INIT_NUM — Configures the waiting time of reading eFuse memory. Measurement unit: One cycle of the eFuse core clock.
  [23:16] TSUR_A — Configures the read setup time (>=14ns). Measurement unit: One cycle of the eFuse core clock.
  [15:8] TRD — Configures the read time (>=52ns). Measurement unit: One cycle of the eFuse core clock.
  [7:0] THR_A — Configures the read hold time (>=14ns). Measurement unit: One cycle of the eFuse core clock.
0x1F4 WR_TIM_CONF1 reset 0x1399A01 — Configurarion register 1 of eFuse programming timing parameters.
  [31:24] THP_A — Configures the programming hold time (>=11ns). Measurement unit: One cycle of the eFuse core clock.
  [23:8] PWR_ON_NUM — Configures the power up time for VDDQ (>reg_dac_clk_div*reg_dac_clk_div). Measurement unit: One cycle of the eFuse core clock.
  [7:0] TSUP_A — Configures the programming setup time (>14ns). Measurement unit: One cycle of the eFuse core clock.
0x1F8 WR_TIM_CONF2 reset 0xF001E0 — Configurarion register 2 of eFuse programming timing parameters.
  [31:16] TPGM — Configures the active programming time (>10us). Measurement unit: One cycle of the eFuse core clock.
  [15:0] PWR_OFF_NUM — Configures the power outage time for VDDQ. Measurement unit: One cycle of the eFuse core clock.
0x1FC WR_TIM_CONF0_RS_BYPASS access per field reset 0x2000 — Configurarion register0 of eFuse programming time parameters and rs bypass operation.
  [20:13] TPGM_INACTIVE rw — Configures the inactive programming time. Measurement unit: One cycle of the eFuse core clock.
  [12] UPDATE wo — Configures whether to update multi-bit register signals.\\ 1: Update\\ 0: No effect\\
  [11:1] BYPASS_RS_BLK_NUM rw — Configures which block number to bypass the Reed-Solomon (RS) correction step.
  [0] BYPASS_RS_CORRECTION rw — Configures whether to bypass the Reed-Solomon (RS) correction step.\\ 0: Not bypass\\ 1: Bypass\\
0x500 WR_DIS — eFuse apb2otp block0 data register1.
  [31:0] BLOCK0_WR_DIS — OTP block0 write disable data.
{0x500+4i} BLK0_BACKUP1_W{i} (i=1..8) — eFuse apb2otp block0 data register{i+1}.
  [31:0] BLOCK0_BACKUP1_W{i} — OTP block0 backup1 word{i} data.
{0x520+4i} BLK0_BACKUP2_W{i} (i=1..8) — eFuse apb2otp block0 data register{i+9}.
  [31:0] BLOCK0_BACKUP2_W{i} — OTP block0 backup2 word{i} data.
{0x540+4i} BLK0_BACKUP3_W{i} (i=1..8) — eFuse apb2otp block0 data register{i+17}.
  [31:0] BLOCK0_BACKUP3_W{i} — OTP block0 backup3 word{i} data.
{0x560+4i} BLK0_BACKUP4_W{i} (i=1..5) — eFuse apb2otp block0 data register{i+25}.
  [31:0] BLOCK0_BACKUP4_W{i} — OTP block0 backup4 word{i} data.
{0x560+4i} BLK0_BACKUP4_W{i} (i=6..8) — eFuse apb2otp block0 data register{i+28}.
  [31:0] BLOCK0_BACKUP4_W{i} — OTP block0 backup4 word{i} data.
{0x580+4i} BLK1_W{i} (i=1..9) — eFuse apb2otp block1 data register{i}.
  [31:0] BLOCK1_W{i} — OTP block1 word{i} data.
{0x5A4+4i} BLK2_W{i} (i=1..11) — eFuse apb2otp block2 data register{i}.
  [31:0] BLOCK2_W{i} — OTP block2 word{i} data.
{0x5D0+4i} BLK3_W{i} (i=1..11) — eFuse apb2otp block3 data register{i}.
  [31:0] BLOCK3_W{i} — OTP block3 word{i} data.
0x600 BLK4_W1 — eFuse apb2otp BLOCK7 data register1.
  [31:0] BLOCK4_W1 — OTP block4 word1 data.
{0x5FC+4i} BLK4_W{i} (i=2..9) — eFuse apb2otp block4 data register{i}.
  [31:0] BLOCK4_W{i} — OTP block4 word{i} data.
0x624 BLK4_W10 — eFuse apb2otp block4 data registe10.
  [31:0] BLOCK4_W10 — OTP block4 word10 data.
0x628 BLK4_W11 — eFuse apb2otp block4 data register11.
  [31:0] BLOCK4_W11 — OTP block4 word11 data.
{0x628+4i} BLK5_W{i} (i=1..11) — eFuse apb2otp block5 data register{i}.
  [31:0] BLOCK5_W{i} — OTP block5 word{i} data.
{0x654+4i} BLK6_W{i} (i=1..11) — eFuse apb2otp block6 data register{i}.
  [31:0] BLOCK6_W{i} — OTP block6 word{i} data.
{0x680+4i} BLK7_W{i} (i=1..11) — eFuse apb2otp block7 data register{i}.
  [31:0] BLOCK7_W{i} — OTP block7 word{i} data.
{0x6AC+4i} BLK8_W{i} (i=1..11) — eFuse apb2otp block8 data register{i}.
  [31:0] BLOCK8_W{i} — OTP block8 word{i} data.
{0x6D8+4i} BLK9_W{i} (i=1..11) — eFuse apb2otp block9 data register{i}.
  [31:0] BLOCK9_W{i} — OTP block9 word{i} data.
0x70C EN — eFuse apb2otp enable configuration register.
  [0] APB2OTP_EN — Apb2otp mode enable signal.
